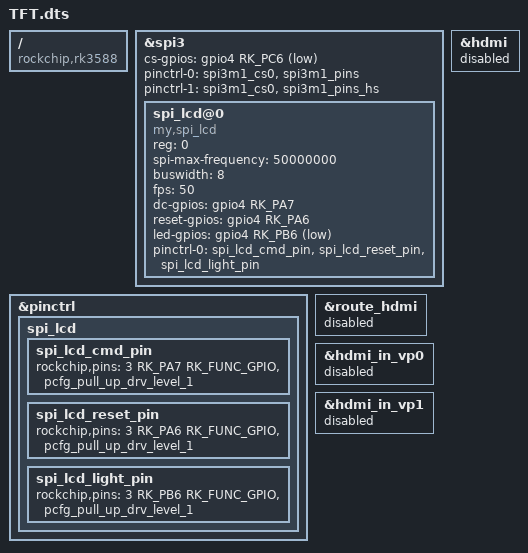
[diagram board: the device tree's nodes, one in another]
/dts-v1/;
/plugin/;

#include <dt-bindings/gpio/gpio.h>
#include <dt-bindings/pinctrl/rockchip.h>
#include <dt-bindings/clock/rk3588-cru.h>
#include <dt-bindings/interrupt-controller/irq.h>


/ {
        compatible = "rockchip,rk3588";

        fragment@0 {
                target = <&spi3>;

                __overlay__ {
                        status = "okay";
            cs-gpios = <&gpio4 RK_PC6 GPIO_ACTIVE_LOW>;
                        #address-cells = <1>;
                        #size-cells = <0>;

            //assigned-clock-rates = <100000000>; //100M
                        // 40PIN引脚只预留SPI3 CS0引脚，如果有多个CS信号，可以使用gpio模拟cs 
                        pinctrl-names = "default", "high_speed";  //引脚状态名字
                        pinctrl-0 = <&spi3m1_cs0 &spi3m1_pins>; //default状态下的引脚配置
                        pinctrl-1 = <&spi3m1_cs0 &spi3m1_pins_hs>; //配置了“high_speed”,驱动会用这个，而不是default

            spi_lcd@0 {
                compatible = "my,spi_lcd";
                reg = <0>; //chip select 0:cs0  1:cs1
                spi-max-frequency = <50000000>; //spi output clock 50M
                buswidth = <8>; //fbtft用的 带宽
                fps = <50>; //fbtft用的 fps
                //指定引用引脚，以及有效电平
                dc-gpios = <&gpio4 RK_PA7 GPIO_ACTIVE_HIGH>; //GPIO4_A7 data/command 103
                reset-gpios = <&gpio4 RK_PA6 GPIO_ACTIVE_HIGH>; //GPIO4_A6 reset 102
                led-gpios = <&gpio4 RK_PB6 GPIO_ACTIVE_LOW>; //GPIO4_B5 back light 101
                pinctrl-names = "default";
                pinctrl-0 = <&spi_lcd_cmd_pin &spi_lcd_reset_pin &spi_lcd_light_pin>;
            };
        };
    };

    fragment@1 {
        target = <&pinctrl>;

        __overlay__ {
            spi_lcd {
                //配置指定引脚的 复用/上下拉/驱动能力 等
                spi_lcd_cmd_pin: spi_lcd_cmd_pin {
                    rockchip,pins = <3 RK_PA7 RK_FUNC_GPIO &pcfg_pull_up_drv_level_1>;
                };
                spi_lcd_reset_pin: spi_lcd_reset_pin {
                    rockchip,pins = <3 RK_PA6 RK_FUNC_GPIO &pcfg_pull_up_drv_level_1>;
                };        
                spi_lcd_light_pin: spi_lcd_light_pin {
                    rockchip,pins = <3 RK_PB6 RK_FUNC_GPIO &pcfg_pull_up_drv_level_1>;
                };
            };

        };

    };

    //下面的是关hdmi，不然小屏幕显示不了？
    fragment@2 {
        target = <&route_hdmi>;

        __overlay__ {
            status = "disabled";
        };
    };


    fragment@3 {
        target = <&hdmi_in_vp0>;

        __overlay__ {
            status = "disabled";
        };
    };

    fragment@4 {
        target = <&hdmi_in_vp1>;

        __overlay__ {
            status = "disabled";
        };
    };       

    fragment@5 {
        target = <&hdmi>;

        __overlay__ {
            status = "disabled";
        };
    };

    
};
